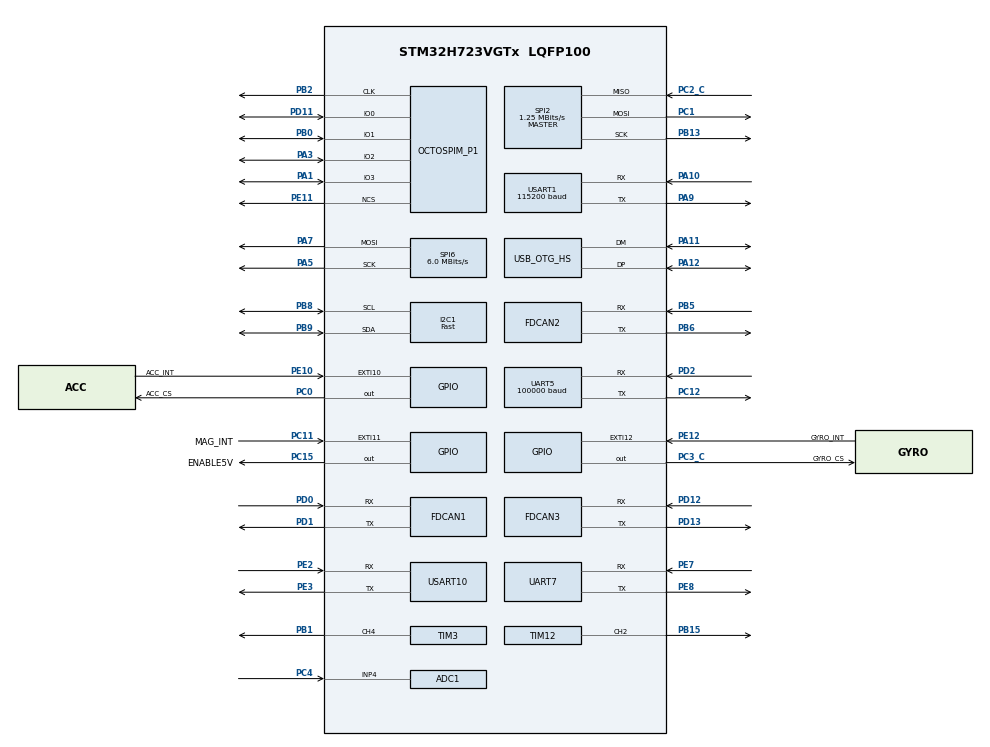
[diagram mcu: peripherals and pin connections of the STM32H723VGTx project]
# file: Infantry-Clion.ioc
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ADC1.Channel-0\#ChannelRegularConversion=ADC_CHANNEL_4
ADC1.Channel-1\#ChannelRegularConversion=ADC_CHANNEL_4
ADC1.ClockPrescaler=ADC_CLOCK_ASYNC_DIV64
ADC1.ClockPrescalerADC3=ADC_CLOCK_ASYNC_DIV4
ADC1.ContinuousConvMode=ENABLE
ADC1.NbrOfConversion=2
ADC1.NbrOfConversionFlag=1
ADC1.OffsetNumber-0\#ChannelRegularConversion=ADC_OFFSET_NONE
ADC1.OffsetNumber-1\#ChannelRegularConversion=ADC_OFFSET_NONE
ADC1.OffsetSignedSaturation-0\#ChannelRegularConversion=DISABLE
ADC1.OffsetSignedSaturation-1\#ChannelRegularConversion=DISABLE
ADC1.Rank-0\#ChannelRegularConversion=1
ADC1.Rank-1\#ChannelRegularConversion=2
ADC1.SamplingTime-0\#ChannelRegularConversion=ADC_SAMPLETIME_32CYCLES_5
ADC1.SamplingTime-1\#ChannelRegularConversion=ADC_SAMPLETIME_32CYCLES_5
ADC1.master=1
ADC3.Channel-1\#ChannelRegularConversion=ADC_CHANNEL_TEMPSENSOR
ADC3.ClockPrescaler=ADC_CLOCK_ASYNC_DIV64
ADC3.ClockPrescalerADC3=ADC_CLOCK_ASYNC_DIV4
ADC3.NbrOfConversionFlag=1
ADC3.OffsetNumber-1\#ChannelRegularConversion=ADC_OFFSET_NONE
ADC3.OffsetSign-1\#ChannelRegularConversion=ADC3_OFFSET_SIGN_NEGATIVE
ADC3.Rank-1\#ChannelRegularConversion=1
ADC3.SamplingTime-1\#ChannelRegularConversion=ADC3_SAMPLETIME_640CYCLES_5
CORTEX_M7.AccessPermission-Cortex_Memory_Protection_Unit_Region0_Settings=MPU_REGION_PRIV_RW_URO
CORTEX_M7.AccessPermission-Cortex_Memory_Protection_Unit_Region1_Settings=MPU_REGION_FULL_ACCESS
CORTEX_M7.BaseAddress-Cortex_Memory_Protection_Unit_Region0_Settings=0x08000000
CORTEX_M7.BaseAddress-Cortex_Memory_Protection_Unit_Region1_Settings=0x20000000
CORTEX_M7.CPU_DCache=Disabled
CORTEX_M7.CPU_ICache=Enabled
CORTEX_M7.Enable-Cortex_Memory_Protection_Unit_Region0_Settings=MPU_REGION_ENABLE
CORTEX_M7.Enable-Cortex_Memory_Protection_Unit_Region1_Settings=MPU_REGION_ENABLE
CORTEX_M7.IsCacheable-Cortex_Memory_Protection_Unit_Region0_Settings=MPU_ACCESS_CACHEABLE
CORTEX_M7.MPU_Control=MPU_PRIVILEGED_DEFAULT
CORTEX_M7.Number-Cortex_Memory_Protection_Unit_Region1_Settings=MPU_REGION_NUMBER1
CORTEX_M7.Size-Cortex_Memory_Protection_Unit_Region0_Settings=MPU_REGION_SIZE_1MB
CORTEX_M7.Size-Cortex_Memory_Protection_Unit_Region1_Settings=MPU_REGION_SIZE_512MB
CORTEX_M7.SubRegionDisable-Cortex_Memory_Protection_Unit_Region1_Settings=0xAC
CORTEX_M7.TypeExtField-Cortex_Memory_Protection_Unit_Region1_Settings=MPU_TEX_LEVEL1
Dma.Request0=USART1_RX
Dma.Request1=USART1_TX
Dma.Request2=UART7_RX
Dma.Request3=UART7_TX
Dma.Request4=USART10_RX
Dma.Request5=USART10_TX
Dma.Request6=SPI2_TX
Dma.Request7=SPI2_RX
Dma.Request8=UART5_RX
Dma.SPI2_RX.7.Direction=DMA_PERIPH_TO_MEMORY
Dma.SPI2_RX.7.EventEnable=DISABLE
Dma.SPI2_RX.7.FIFOMode=DMA_FIFOMODE_DISABLE
Dma.SPI2_RX.7.Instance=DMA1_Stream7
Dma.SPI2_RX.7.MemDataAlignment=DMA_MDATAALIGN_BYTE
Dma.SPI2_RX.7.MemInc=DMA_MINC_ENABLE
Dma.SPI2_RX.7.Mode=DMA_NORMAL
Dma.SPI2_RX.7.PeriphDataAlignment=DMA_PDATAALIGN_BYTE
Dma.SPI2_RX.7.PeriphInc=DMA_PINC_DISABLE
Dma.SPI2_RX.7.Polarity=HAL_DMAMUX_REQ_GEN_RISING
Dma.SPI2_RX.7.Priority=DMA_PRIORITY_VERY_HIGH
Dma.SPI2_RX.7.RequestNumber=1
Dma.SPI2_RX.7.SignalID=NONE
Dma.SPI2_RX.7.SyncEnable=DISABLE
Dma.SPI2_RX.7.SyncPolarity=HAL_DMAMUX_SYNC_NO_EVENT
Dma.SPI2_RX.7.SyncRequestNumber=1
Dma.SPI2_RX.7.SyncSignalID=NONE
Dma.SPI2_TX.6.Direction=DMA_MEMORY_TO_PERIPH
Dma.SPI2_TX.6.EventEnable=DISABLE
Dma.SPI2_TX.6.FIFOMode=DMA_FIFOMODE_DISABLE
Dma.SPI2_TX.6.Instance=DMA1_Stream6
Dma.SPI2_TX.6.MemDataAlignment=DMA_MDATAALIGN_BYTE
Dma.SPI2_TX.6.MemInc=DMA_MINC_ENABLE
Dma.SPI2_TX.6.Mode=DMA_NORMAL
Dma.SPI2_TX.6.PeriphDataAlignment=DMA_PDATAALIGN_BYTE
Dma.SPI2_TX.6.PeriphInc=DMA_PINC_DISABLE
Dma.SPI2_TX.6.Polarity=HAL_DMAMUX_REQ_GEN_RISING
Dma.SPI2_TX.6.Priority=DMA_PRIORITY_HIGH
Dma.SPI2_TX.6.RequestNumber=1
Dma.SPI2_TX.6.SignalID=NONE
Dma.SPI2_TX.6.SyncEnable=DISABLE
Dma.SPI2_TX.6.SyncPolarity=HAL_DMAMUX_SYNC_NO_EVENT
Dma.SPI2_TX.6.SyncRequestNumber=1
Dma.SPI2_TX.6.SyncSignalID=NONE
Dma.UART5_RX.8.Direction=DMA_PERIPH_TO_MEMORY
Dma.UART5_RX.8.EventEnable=DISABLE
Dma.UART5_RX.8.FIFOMode=DMA_FIFOMODE_DISABLE
Dma.UART5_RX.8.Instance=DMA1_Stream0
Dma.UART5_RX.8.MemDataAlignment=DMA_MDATAALIGN_BYTE
Dma.UART5_RX.8.MemInc=DMA_MINC_ENABLE
Dma.UART5_RX.8.Mode=DMA_NORMAL
Dma.UART5_RX.8.PeriphDataAlignment=DMA_PDATAALIGN_BYTE
Dma.UART5_RX.8.PeriphInc=DMA_PINC_DISABLE
Dma.UART5_RX.8.Polarity=HAL_DMAMUX_REQ_GEN_RISING
Dma.UART5_RX.8.Priority=DMA_PRIORITY_HIGH
Dma.UART5_RX.8.RequestNumber=1
Dma.UART5_RX.8.SignalID=NONE
Dma.UART5_RX.8.SyncEnable=DISABLE
Dma.UART5_RX.8.SyncPolarity=HAL_DMAMUX_SYNC_NO_EVENT
Dma.UART5_RX.8.SyncRequestNumber=1
Dma.UART5_RX.8.SyncSignalID=NONE
Dma.UART7_RX.2.Direction=DMA_PERIPH_TO_MEMORY
Dma.UART7_RX.2.EventEnable=DISABLE
Dma.UART7_RX.2.FIFOMode=DMA_FIFOMODE_DISABLE
Dma.UART7_RX.2.Instance=DMA1_Stream2
Dma.UART7_RX.2.MemDataAlignment=DMA_MDATAALIGN_BYTE
Dma.UART7_RX.2.MemInc=DMA_MINC_ENABLE
Dma.UART7_RX.2.Mode=DMA_NORMAL
Dma.UART7_RX.2.PeriphDataAlignment=DMA_PDATAALIGN_BYTE
Dma.UART7_RX.2.PeriphInc=DMA_PINC_DISABLE
Dma.UART7_RX.2.Polarity=HAL_DMAMUX_REQ_GEN_RISING
Dma.UART7_RX.2.Priority=DMA_PRIORITY_VERY_HIGH
Dma.UART7_RX.2.RequestNumber=1
Dma.UART7_RX.2.SignalID=NONE
Dma.UART7_RX.2.SyncEnable=DISABLE
Dma.UART7_RX.2.SyncPolarity=HAL_DMAMUX_SYNC_NO_EVENT
Dma.UART7_RX.2.SyncRequestNumber=1
Dma.UART7_RX.2.SyncSignalID=NONE
Dma.UART7_TX.3.Direction=DMA_MEMORY_TO_PERIPH
Dma.UART7_TX.3.EventEnable=DISABLE
Dma.UART7_TX.3.FIFOMode=DMA_FIFOMODE_DISABLE
Dma.UART7_TX.3.Instance=DMA1_Stream3
Dma.UART7_TX.3.MemDataAlignment=DMA_MDATAALIGN_BYTE
Dma.UART7_TX.3.MemInc=DMA_MINC_ENABLE
Dma.UART7_TX.3.Mode=DMA_NORMAL
Dma.UART7_TX.3.PeriphDataAlignment=DMA_PDATAALIGN_BYTE
Dma.UART7_TX.3.PeriphInc=DMA_PINC_DISABLE
Dma.UART7_TX.3.Polarity=HAL_DMAMUX_REQ_GEN_RISING
Dma.UART7_TX.3.Priority=DMA_PRIORITY_VERY_HIGH
Dma.UART7_TX.3.RequestNumber=1
Dma.UART7_TX.3.SignalID=NONE
Dma.UART7_TX.3.SyncEnable=DISABLE
Dma.UART7_TX.3.SyncPolarity=HAL_DMAMUX_SYNC_NO_EVENT
Dma.UART7_TX.3.SyncRequestNumber=1
Dma.UART7_TX.3.SyncSignalID=NONE
Dma.USART10_RX.4.Direction=DMA_PERIPH_TO_MEMORY
Dma.USART10_RX.4.EventEnable=DISABLE
Dma.USART10_RX.4.FIFOMode=DMA_FIFOMODE_DISABLE
Dma.USART10_RX.4.Instance=DMA1_Stream4
Dma.USART10_RX.4.MemDataAlignment=DMA_MDATAALIGN_BYTE
Dma.USART10_RX.4.MemInc=DMA_MINC_ENABLE
Dma.USART10_RX.4.Mode=DMA_NORMAL
Dma.USART10_RX.4.PeriphDataAlignment=DMA_PDATAALIGN_BYTE
Dma.USART10_RX.4.PeriphInc=DMA_PINC_DISABLE
Dma.USART10_RX.4.Polarity=HAL_DMAMUX_REQ_GEN_RISING
Dma.USART10_RX.4.Priority=DMA_PRIORITY_VERY_HIGH
Dma.USART10_RX.4.RequestNumber=1
Dma.USART10_RX.4.SignalID=NONE
Dma.USART10_RX.4.SyncEnable=DISABLE
Dma.USART10_RX.4.SyncPolarity=HAL_DMAMUX_SYNC_NO_EVENT
Dma.USART10_RX.4.SyncRequestNumber=1
Dma.USART10_RX.4.SyncSignalID=NONE
Dma.USART10_TX.5.Direction=DMA_MEMORY_TO_PERIPH
Dma.USART10_TX.5.EventEnable=DISABLE
Dma.USART10_TX.5.FIFOMode=DMA_FIFOMODE_DISABLE
Dma.USART10_TX.5.Instance=DMA1_Stream5
Dma.USART10_TX.5.MemDataAlignment=DMA_MDATAALIGN_BYTE
Dma.USART10_TX.5.MemInc=DMA_MINC_ENABLE
Dma.USART10_TX.5.Mode=DMA_NORMAL
Dma.USART10_TX.5.PeriphDataAlignment=DMA_PDATAALIGN_BYTE
Dma.USART10_TX.5.PeriphInc=DMA_PINC_DISABLE
Dma.USART10_TX.5.Polarity=HAL_DMAMUX_REQ_GEN_RISING
Dma.USART10_TX.5.Priority=DMA_PRIORITY_VERY_HIGH
Dma.USART10_TX.5.RequestNumber=1
Dma.USART10_TX.5.SignalID=NONE
Dma.USART10_TX.5.SyncEnable=DISABLE
Dma.USART10_TX.5.SyncPolarity=HAL_DMAMUX_SYNC_NO_EVENT
Dma.USART10_TX.5.SyncRequestNumber=1
Dma.USART10_TX.5.SyncSignalID=NONE
Dma.USART1_RX.0.Direction=DMA_PERIPH_TO_MEMORY
Dma.USART1_RX.0.EventEnable=DISABLE
Dma.USART1_RX.0.FIFOMode=DMA_FIFOMODE_DISABLE
Dma.USART1_RX.0.Instance=DMA1_Stream1
Dma.USART1_RX.0.MemDataAlignment=DMA_MDATAALIGN_BYTE
Dma.USART1_RX.0.MemInc=DMA_MINC_ENABLE
Dma.USART1_RX.0.Mode=DMA_NORMAL
Dma.USART1_RX.0.PeriphDataAlignment=DMA_PDATAALIGN_BYTE
Dma.USART1_RX.0.PeriphInc=DMA_PINC_DISABLE
Dma.USART1_RX.0.Polarity=HAL_DMAMUX_REQ_GEN_RISING
Dma.USART1_RX.0.Priority=DMA_PRIORITY_VERY_HIGH
Dma.USART1_RX.0.RequestNumber=1
Dma.USART1_RX.0.SignalID=NONE
Dma.USART1_RX.0.SyncEnable=DISABLE
Dma.USART1_RX.0.SyncPolarity=HAL_DMAMUX_SYNC_NO_EVENT
Dma.USART1_RX.0.SyncRequestNumber=1
Dma.USART1_RX.0.SyncSignalID=NONE
Dma.USART1_TX.1.Direction=DMA_MEMORY_TO_PERIPH
Dma.USART1_TX.1.EventEnable=DISABLE
Dma.USART1_TX.1.FIFOMode=DMA_FIFOMODE_DISABLE
Dma.USART1_TX.1.Instance=DMA2_Stream0
Dma.USART1_TX.1.MemDataAlignment=DMA_MDATAALIGN_BYTE
Dma.USART1_TX.1.MemInc=DMA_MINC_ENABLE
Dma.USART1_TX.1.Mode=DMA_NORMAL
Dma.USART1_TX.1.PeriphDataAlignment=DMA_PDATAALIGN_BYTE
Dma.USART1_TX.1.PeriphInc=DMA_PINC_DISABLE
Dma.USART1_TX.1.Polarity=HAL_DMAMUX_REQ_GEN_RISING
Dma.USART1_TX.1.Priority=DMA_PRIORITY_VERY_HIGH
Dma.USART1_TX.1.RequestNumber=1
Dma.USART1_TX.1.SignalID=NONE
Dma.USART1_TX.1.SyncEnable=DISABLE
Dma.USART1_TX.1.SyncPolarity=HAL_DMAMUX_SYNC_NO_EVENT
Dma.USART1_TX.1.SyncRequestNumber=1
Dma.USART1_TX.1.SyncSignalID=NONE
FDCAN1.AutoRetransmission=ENABLE
FDCAN1.CalculateBaudRateNominal=1000000
FDCAN1.CalculateTimeBitNominal=1000
FDCAN1.CalculateTimeQuantumNominal=50.0
FDCAN1.DataPrescaler=1
FDCAN1.DataSyncJumpWidth=2
FDCAN1.DataTimeSeg1=13
FDCAN1.DataTimeSeg2=2
FDCAN1.ExtFiltersNbr=0
FDCAN1.Mode=FDCAN_MODE_NORMAL
FDCAN1.NominalPrescaler=1
FDCAN1.NominalSyncJumpWidth=20
FDCAN1.NominalTimeSeg1=14
FDCAN1.NominalTimeSeg2=5
FDCAN1.ProtocolException=ENABLE
FDCAN1.RxBuffersNbr=0
FDCAN1.RxFifo0ElmtsNbr=4
FDCAN1.RxFifo1ElmtsNbr=0
FDCAN1.StdFiltersNbr=1
FDCAN1.TxBuffersNbr=0
FDCAN1.TxEventsNbr=0
FDCAN1.TxFifoQueueElmtsNbr=4
FDCAN1.TxFifoQueueMode=FDCAN_TX_FIFO_OPERATION
FDCAN2.AutoRetransmission=ENABLE
FDCAN2.CalculateBaudRateNominal=1000000
FDCAN2.CalculateTimeBitNominal=1000
FDCAN2.CalculateTimeQuantumNominal=50.0
FDCAN2.DataSyncJumpWidth=2
FDCAN2.DataTimeSeg1=13
FDCAN2.DataTimeSeg2=2
FDCAN2.ExtFiltersNbr=0
FDCAN2.MessageRAMOffset=0x300
FDCAN2.Mode=FDCAN_MODE_NORMAL
FDCAN2.NominalPrescaler=1
FDCAN2.NominalSyncJumpWidth=20
FDCAN2.NominalTimeSeg1=14
FDCAN2.NominalTimeSeg2=5
FDCAN2.ProtocolException=ENABLE
FDCAN2.RxBuffersNbr=0
FDCAN2.RxFifo0ElmtsNbr=4
FDCAN2.RxFifo1ElmtsNbr=0
FDCAN2.StdFiltersNbr=1
FDCAN2.TxBuffersNbr=0
FDCAN2.TxEventsNbr=0
FDCAN2.TxFifoQueueElmtsNbr=4
FDCAN3.AutoRetransmission=ENABLE
FDCAN3.CalculateBaudRateNominal=1000000
FDCAN3.CalculateTimeBitNominal=1000
FDCAN3.CalculateTimeQuantumNominal=50.0
FDCAN3.DataSyncJumpWidth=2
FDCAN3.DataTimeSeg1=13
FDCAN3.DataTimeSeg2=2
FDCAN3.ExtFiltersNbr=0
FDCAN3.MessageRAMOffset=0x600
FDCAN3.Mode=FDCAN_MODE_NORMAL
FDCAN3.NominalPrescaler=1
FDCAN3.NominalSyncJumpWidth=20
FDCAN3.NominalTimeSeg1=14
FDCAN3.NominalTimeSeg2=5
FDCAN3.ProtocolException=ENABLE
FDCAN3.RxBuffersNbr=0
FDCAN3.RxFifo0ElmtsNbr=4
FDCAN3.RxFifo1ElmtsNbr=0
FDCAN3.StdFiltersNbr=1
FDCAN3.TxBuffersNbr=0
FDCAN3.TxEventsNbr=0
FDCAN3.TxFifoQueueElmtsNbr=4
FREERTOS.BinarySemaphores01=imuBinarySem01,Dynamic,NULL,Available
FREERTOS.INCLUDE_xEventGroupSetBitFromISR=1
FREERTOS.INCLUDE_xSemaphoreGetMutexHolder=1
FREERTOS.INCLUDE_xTaskGetHandle=1
FREERTOS.Tasks01=defaultTask,24,128,StartDefaultTask,Default,NULL,Dynamic,NULL,NULL;ledTask,8,128,led_task,As external,NULL,Dynamic,NULL,NULL;imuTask,49,128,imu_task,As external,NULL,Dynamic,NULL,NULL;usbTask,8,128,usb_task,As external,NULL,Dynamic,NULL,NULL;refereeTask,8,128,referee_task,As external,NULL,Dynamic,NULL,NULL;chassisTask,40,128,chassis_task,As external,NULL,Dynamic,NULL,NULL;detectTask,8,128,detect_task,As external,NULL,Dynamic,NULL,NULL;remoteControlTa,8,128,remote_control_task,As external,NULL,Dynamic,NULL,NULL;gimbalTask,48,128,gimbal_task,As external,NULL,Dynamic,NULL,NULL;buzzerTask,8,128,buzzer_task,As external,NULL,Dynamic,NULL,NULL;shootTask,43,128,shoot_task,As external,NULL,Dynamic,NULL,NULL;watchTask,48,128,watch_task,As external,NULL,Dynamic,NULL,NULL;uiTask,8,128,ui_task,As external,NULL,Dynamic,NULL,NULL;autoShoot,48,128,auto_shoot_task,As external,NULL,Dynamic,NULL,NULL
FREERTOS.configENABLE_FPU=1
FREERTOS.configGENERATE_RUN_TIME_STATS=1
FREERTOS.configLIBRARY_MAX_SYSCALL_INTERRUPT_PRIORITY=5
FREERTOS.configUSE_NEWLIB_REENTRANT=1
FREERTOS.configUSE_STATS_FORMATTING_FUNCTIONS=1
I2C1.CustomTiming=Disabled
I2C1.I2C_Speed_Mode=I2C_Fast
I2C1.Timing=0x00B03FDB
Mcu.Family=STM32H7
Mcu.Name=STM32H723VGTx
Mcu.Package=LQFP100
NVIC.DMA1_Stream0_IRQn=true\:5\:0\:false\:false\:true\:true\:false\:true\:true
NVIC.DMA1_Stream1_IRQn=true\:5\:0\:false\:false\:true\:true\:false\:true\:true
NVIC.DMA1_Stream2_IRQn=true\:5\:0\:false\:false\:true\:true\:false\:true\:true
NVIC.DMA1_Stream3_IRQn=true\:5\:0\:false\:false\:true\:true\:false\:true\:true
NVIC.DMA1_Stream4_IRQn=true\:5\:0\:false\:false\:true\:true\:false\:true\:true
NVIC.DMA1_Stream5_IRQn=true\:5\:0\:false\:false\:true\:true\:false\:true\:true
NVIC.DMA1_Stream6_IRQn=true\:5\:0\:false\:false\:true\:true\:false\:true\:true
NVIC.DMA1_Stream7_IRQn=true\:5\:0\:false\:false\:true\:true\:false\:true\:true
NVIC.DMA2_Stream0_IRQn=true\:5\:0\:false\:false\:true\:true\:false\:true\:true
NVIC.EXTI15_10_IRQn=true\:10\:0\:true\:false\:true\:true\:true\:true\:true
NVIC.FDCAN1_IT0_IRQn=true\:5\:0\:true\:false\:true\:true\:true\:true\:true
NVIC.FDCAN2_IT0_IRQn=true\:5\:0\:false\:false\:true\:true\:true\:true\:true
NVIC.FDCAN3_IT0_IRQn=true\:5\:0\:true\:false\:true\:true\:true\:true\:true
NVIC.FDCAN3_IT1_IRQn=true\:5\:0\:false\:false\:true\:true\:true\:true\:true
NVIC.OTG_HS_IRQn=true\:5\:0\:false\:false\:true\:true\:true\:true\:true
NVIC.PriorityGroup=NVIC_PRIORITYGROUP_4
NVIC.SPI2_IRQn=true\:5\:0\:false\:false\:true\:true\:false\:true\:true
NVIC.TIM17_IRQn=true\:5\:0\:false\:false\:true\:true\:true\:true\:true
NVIC.TIM1_UP_IRQn=true\:5\:0\:true\:false\:true\:false\:false\:true\:true
NVIC.TIM24_IRQn=true\:5\:0\:false\:false\:true\:true\:true\:true\:true
NVIC.TimeBase=TIM1_UP_IRQn
NVIC.TimeBaseIP=TIM1
NVIC.UART5_IRQn=true\:5\:0\:false\:false\:true\:true\:true\:true\:true
NVIC.UART7_IRQn=true\:5\:0\:false\:false\:true\:true\:true\:true\:true
NVIC.USART10_IRQn=true\:5\:0\:false\:false\:true\:true\:true\:true\:true
NVIC.USART1_IRQn=true\:5\:0\:false\:false\:true\:true\:true\:true\:true
OCTOSPI2.ClockMode=HAL_OSPI_CLOCK_MODE_3
OCTOSPI2.ClockPrescaler=3
OCTOSPI2.DeviceSize=23
OCTOSPI2.DeviceType=SPI_DEVICE_FLASH
OCTOSPI2.FifoThreshold=8
OCTOSPI2.SampleShifting=HAL_OSPI_SAMPLE_SHIFTING_HALFCYCLE
PA1.Mode=OCTOSPI2_IOL_Port1L
PA1.Signal=OCTOSPIM_P1_IO3
PA10.Mode=Asynchronous
PA10.Signal=USART1_RX
PA11.Mode=Device_Only_FS
PA11.Signal=USB_OTG_HS_DM
PA12.Mode=Device_Only_FS
PA12.Signal=USB_OTG_HS_DP
PA13(JTMS/SWDIO).Mode=Serial_Wire
PA13(JTMS/SWDIO).Signal=DEBUG_JTMS-SWDIO
PA14(JTCK/SWCLK).Mode=Serial_Wire
PA14(JTCK/SWCLK).Signal=DEBUG_JTCK-SWCLK
PA3.Mode=OCTOSPI2_IOL_Port1L
PA3.Signal=OCTOSPIM_P1_IO2
PA5.GPIO_PuPd=GPIO_NOPULL
PA5.GPIO_Speed=GPIO_SPEED_FREQ_VERY_HIGH
PA5.Mode=TX_Only_Simplex_Unidirect_Master
PA5.Signal=SPI6_SCK
PA7.GPIO_PuPd=GPIO_NOPULL
PA7.GPIO_Speed=GPIO_SPEED_FREQ_VERY_HIGH
PA7.Mode=TX_Only_Simplex_Unidirect_Master
PA7.Signal=SPI6_MOSI
PA9.Mode=Asynchronous
PA9.Signal=USART1_TX
PB0.Mode=OCTOSPI2_IOL_Port1L
PB0.Signal=OCTOSPIM_P1_IO1
PB1.Signal=S_TIM3_CH4
PB13.Mode=Full_Duplex_Master
PB13.Signal=SPI2_SCK
PB15.GPIO_Speed=GPIO_SPEED_FREQ_HIGH
PB15.Signal=S_TIM12_CH2
PB2.Mode=O2_P1_CLK
PB2.Signal=OCTOSPIM_P1_CLK
PB5.Mode=FDCAN_Activate
PB5.Signal=FDCAN2_RX
PB6.Mode=FDCAN_Activate
PB6.Signal=FDCAN2_TX
PB8.GPIO_Speed=GPIO_SPEED_FREQ_HIGH
PB8.Mode=I2C
PB8.Signal=I2C1_SCL
PB9.GPIO_Speed=GPIO_SPEED_FREQ_HIGH
PB9.Mode=I2C
PB9.Signal=I2C1_SDA
PC0.GPIO_Label=ACC_CS
PC0.GPIO_Speed=GPIO_SPEED_FREQ_VERY_HIGH
PC0.PinState=GPIO_PIN_SET
PC0.Signal=GPIO_Output
PC1.Mode=Full_Duplex_Master
PC1.Signal=SPI2_MOSI
PC11.GPIO_Label=MAG_INT
PC11.Signal=GPXTI11
PC12.GPIO_ModeDefaultPP=GPIO_MODE_AF_PP
PC12.Mode=Asynchronous
PC12.Signal=UART5_TX
PC15-OSC32_OUT.GPIO_Label=ENABLE5V
PC15-OSC32_OUT.GPIO_PuPd=GPIO_NOPULL
PC15-OSC32_OUT.PinState=GPIO_PIN_SET
PC15-OSC32_OUT.Signal=GPIO_Output
PC2_C.Mode=Full_Duplex_Master
PC2_C.Signal=SPI2_MISO
PC3_C.GPIO_Label=GYRO_CS
PC3_C.GPIO_Speed=GPIO_SPEED_FREQ_VERY_HIGH
PC3_C.PinState=GPIO_PIN_SET
PC3_C.Signal=GPIO_Output
PC4.Signal=ADCx_INP4
PD0.Mode=FDCAN_Activate
PD0.Signal=FDCAN1_RX
PD1.Mode=FDCAN_Activate
PD1.Signal=FDCAN1_TX
PD11.Mode=OCTOSPI2_IOL_Port1L
PD11.Signal=OCTOSPIM_P1_IO0
PD12.Mode=FDCAN_Activate
PD12.Signal=FDCAN3_RX
PD13.Mode=FDCAN_Activate
PD13.Signal=FDCAN3_TX
PD2.GPIO_ModeDefaultPP=GPIO_MODE_AF_PP
PD2.Mode=Asynchronous
PD2.Signal=UART5_RX
PE10.GPIO_Label=ACC_INT
PE10.Signal=GPXTI10
PE11.Mode=OCTOSPI2_Port1_NCS
PE11.Signal=OCTOSPIM_P1_NCS
PE12.GPIO_Label=GYRO_INT
PE12.Signal=GPXTI12
PE2.Mode=Asynchronous
PE2.Signal=USART10_RX
PE3.Mode=Asynchronous
PE3.Signal=USART10_TX
PE7.Mode=Asynchronous
PE7.Signal=UART7_RX
PE8.Mode=Asynchronous
PE8.Signal=UART7_TX
PH0-OSC_IN.Mode=HSE-External-Oscillator
PH0-OSC_IN.Signal=RCC_OSC_IN
PH1-OSC_OUT.Mode=HSE-External-Oscillator
PH1-OSC_OUT.Signal=RCC_OSC_OUT
ProjectManager.HeapSize=0x200
ProjectManager.StackSize=0x400
ProjectManager.TargetToolchain=STM32CubeIDE
RCC.ADCFreq_Value=96000000
RCC.APB1Freq_Value=120000000
RCC.APB2Freq_Value=120000000
RCC.APB3Freq_Value=120000000
RCC.APB4Freq_Value=120000000
RCC.CortexFreq_Value=480000000
RCC.D1PPRE=RCC_APB3_DIV2
RCC.D2PPRE1=RCC_APB1_DIV2
RCC.D2PPRE2=RCC_APB2_DIV2
RCC.D3PPRE=RCC_APB4_DIV2
RCC.DIVM1=2
RCC.DIVM2=2
RCC.DIVN1=40
RCC.DIVN2=16
RCC.DIVP1=1
RCC.DIVQ1=24
RCC.HCLKFreq_Value=240000000
RCC.HPRE=RCC_HCLK_DIV2
RCC.HSE_VALUE=24000000
RCC.PLL2FRACN=0
RCC.PLLFRACN=0
RCC.PLLSourceVirtual=RCC_PLLSOURCE_HSE
RCC.SPI6CLockSelection=RCC_SPI6CLKSOURCE_HSE
RCC.SYSCLKFreq_VALUE=480000000
RCC.SYSCLKSource=RCC_SYSCLKSOURCE_PLLCLK
RCC.USBCLockSelection=RCC_USBCLKSOURCE_HSI48
RCC.USBFreq_Value=48000000
SH.ADCx_INP4.0=ADC1_INP4,IN4-Single-Ended
SH.S_TIM12_CH2.0=TIM12_CH2,PWM Generation2 CH2
SH.S_TIM3_CH4.0=TIM3_CH4,PWM Generation4 CH4
SPI2.BaudRatePrescaler=SPI_BAUDRATEPRESCALER_16
SPI2.CLKPhase=SPI_PHASE_2EDGE
SPI2.CLKPolarity=SPI_POLARITY_HIGH
SPI2.CalculateBaudRate=1.25 MBits/s
SPI2.DataSize=SPI_DATASIZE_8BIT
SPI2.Direction=SPI_DIRECTION_2LINES
SPI2.Mode=SPI_MODE_MASTER
SPI2.VirtualType=VM_MASTER
SPI6.BaudRatePrescaler=SPI_BAUDRATEPRESCALER_4
SPI6.CLKPhase=SPI_PHASE_2EDGE
SPI6.CalculateBaudRate=6.0 MBits/s
SPI6.DataSize=SPI_DATASIZE_8BIT
SPI6.Direction=SPI_DIRECTION_2LINES_TXONLY
SPI6.Mode=SPI_MODE_MASTER
SPI6.VirtualType=VM_MASTER
STMicroelectronics.X-CUBE-ALGOBUILD.1.4.0.LibraryCcDSPOoLibraryJjDSPOoLibrary=true
TIM12.AutoReloadPreload=TIM_AUTORELOAD_PRELOAD_DISABLE
TIM12.Channel-PWM\ Generation2\ CH2=TIM_CHANNEL_2
TIM12.Period=2000-1
TIM12.Prescaler=24-1
TIM12.Pulse-PWM\ Generation2\ CH2=1000
TIM17.AutoReloadPreload=TIM_AUTORELOAD_PRELOAD_ENABLE
TIM17.Period=200
TIM17.Prescaler=239
TIM24.AutoReloadPreload=TIM_AUTORELOAD_PRELOAD_ENABLE
TIM24.Period=399
TIM24.Prescaler=12-1
TIM3.AutoReloadPreload=TIM_AUTORELOAD_PRELOAD_ENABLE
TIM3.Channel-PWM\ Generation4\ CH4=TIM_CHANNEL_4
TIM3.ClockDivision=TIM_CLOCKDIVISION_DIV1
TIM3.Period=12500-1
TIM3.Prescaler=24-1
UART5.BaudRate=100000
UART5.Mode=MODE_RX
UART5.Parity=PARITY_EVEN
UART5.StopBits=UART_STOPBITS_2
UART5.SwapParam=UART_ADVFEATURE_SWAP_DISABLE
UART5.WordLength=WORDLENGTH_9B
USART1.BaudRate=115200
USART1.VirtualMode-Asynchronous=VM_ASYNC
USART10.VirtualMode=VM_ASYNC
USB_DEVICE.CLASS_NAME_HS=CDC
USB_DEVICE.VirtualMode=Cdc
USB_DEVICE.VirtualModeHS=Cdc_HS
USB_OTG_HS.VirtualMode-Device_Only_FS=Device_Only_FS
VP_ADC3_TempSens_Input.Mode=IN-TempSens
VP_ADC3_Vref_Input.Mode=IN-Vrefint
VP_CRC_VS_CRC.Mode=CRC_Activate
VP_FREERTOS_VS_CMSIS_V2.Mode=CMSIS_V2
VP_MEMORYMAP_VS_MEMORYMAP.Mode=CurAppReg
VP_OCTOSPI2_VS_quad.Mode=quad_mode
VP_STMicroelectronics.X-CUBE-ALGOBUILD_VS_DSPOoLibraryJjLibrary_1.4.0_1.4.0.Mode=DSPOoLibraryJjLibrary
VP_SYS_VS_tim1.Mode=TIM1
VP_TIM17_VS_ClockSourceINT.Mode=Enable_Timer
VP_TIM24_VS_ClockSourceINT.Mode=Internal
VP_TIM3_VS_ClockSourceINT.Mode=Internal
VP_USB_DEVICE_VS_USB_DEVICE_CDC_HS.Mode=CDC_HS
board=custom

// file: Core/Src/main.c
/* USER CODE BEGIN Header */
/**
  ******************************************************************************
  * @file           : main.c
  * @brief          : Main program body
  ******************************************************************************
  * @attention
  *
  * Copyright (c) 2024 STMicroelectronics.
  * All rights reserved.
  *
  * This software is licensed under terms that can be found in the LICENSE file
  * in the root directory of this software component.
  * If no LICENSE file comes with this software, it is provided AS-IS.
  *
  ******************************************************************************
  */
/* USER CODE END Header */
#include "main.h"
#include "cmsis_os.h"
#include "adc.h"
#include "crc.h"
#include "dma.h"
#include "fdcan.h"
#include "i2c.h"
#include "memorymap.h"
#include "octospi.h"
#include "spi.h"
#include "tim.h"
#include "usart.h"
#include "usb_device.h"
#include "gpio.h"

/* USER CODE BEGIN Includes */
#include "bsp_can.h"
#include "bsp_tim.h"
/* USER CODE END Includes */

void SystemClock_Config(void);
void PeriphCommonClock_Config(void);
static void MPU_Config(void);
void MX_FREERTOS_Init(void);

int main(void)
{

  /* MPU Configuration--------------------------------------------------------*/
  MPU_Config();

  /* Enable the CPU Cache */

  /* Enable I-Cache---------------------------------------------------------*/
  SCB_EnableICache();

  /* MCU Configuration--------------------------------------------------------*/

  /* Reset of all peripherals, Initializes the Flash interface and the Systick. */
  HAL_Init();

  /* Configure the system clock */
  SystemClock_Config();

  /* Configure the peripherals common clocks */
  PeriphCommonClock_Config();

  /* Initialize all configured peripherals */
  MX_GPIO_Init();
  MX_DMA_Init();
  MX_FDCAN1_Init();
  MX_FDCAN2_Init();
  MX_FDCAN3_Init();
  MX_USART1_UART_Init();
  MX_ADC1_Init();
  MX_ADC3_Init();
  MX_TIM12_Init();
  MX_CRC_Init();
  MX_UART7_Init();
  MX_USART10_UART_Init();
  MX_SPI2_Init();
  MX_TIM3_Init();
  MX_UART5_Init();
  MX_SPI6_Init();
  MX_I2C1_Init();
  MX_TIM24_Init();
  MX_OCTOSPI2_Init();
  MX_TIM17_Init();
  /* USER CODE BEGIN 2 */
  MX_USB_DEVICE_Init();
  fdcan1_filter_init();
  fdcan2_filter_init();
  fdcan3_filter_init();

  /* USER CODE END 2 */

  /* Init scheduler */
  osKernelInitialize();

  /* Call init function for freertos objects (in cmsis_os2.c) */
  MX_FREERTOS_Init();

  /* Start scheduler */
  osKernelStart();

  /* We should never get here as control is now taken by the scheduler */

  /* Infinite loop */
	while (1)
	{

	}
}

void SystemClock_Config(void)
{
  RCC_OscInitTypeDef RCC_OscInitStruct = {0};
  RCC_ClkInitTypeDef RCC_ClkInitStruct = {0};

  /** Supply configuration update enable
  */
  HAL_PWREx_ConfigSupply(PWR_LDO_SUPPLY);

  /** Configure the main internal regulator output voltage
  */
  __HAL_PWR_VOLTAGESCALING_CONFIG(PWR_REGULATOR_VOLTAGE_SCALE0);

  while(!__HAL_PWR_GET_FLAG(PWR_FLAG_VOSRDY)) {}

  /** Initializes the RCC Oscillators according to the specified parameters
  * in the RCC_OscInitTypeDef structure.
  */
  RCC_OscInitStruct.OscillatorType = RCC_OSCILLATORTYPE_HSI48|RCC_OSCILLATORTYPE_HSE;
  RCC_OscInitStruct.HSEState = RCC_HSE_ON;
  RCC_OscInitStruct.HSI48State = RCC_HSI48_ON;
  RCC_OscInitStruct.PLL.PLLState = RCC_PLL_ON;
  RCC_OscInitStruct.PLL.PLLSource = RCC_PLLSOURCE_HSE;
  RCC_OscInitStruct.PLL.PLLM = 2;
  RCC_OscInitStruct.PLL.PLLN = 40;
  RCC_OscInitStruct.PLL.PLLP = 1;
  RCC_OscInitStruct.PLL.PLLQ = 24;
  RCC_OscInitStruct.PLL.PLLR = 2;
  RCC_OscInitStruct.PLL.PLLRGE = RCC_PLL1VCIRANGE_3;
  RCC_OscInitStruct.PLL.PLLVCOSEL = RCC_PLL1VCOWIDE;
  RCC_OscInitStruct.PLL.PLLFRACN = 0;
  if (HAL_RCC_OscConfig(&RCC_OscInitStruct) != HAL_OK)
  {
    Error_Handler();
  }

  /** Initializes the CPU, AHB and APB buses clocks
  */
  RCC_ClkInitStruct.ClockType = RCC_CLOCKTYPE_HCLK|RCC_CLOCKTYPE_SYSCLK
                              |RCC_CLOCKTYPE_PCLK1|RCC_CLOCKTYPE_PCLK2
                              |RCC_CLOCKTYPE_D3PCLK1|RCC_CLOCKTYPE_D1PCLK1;
  RCC_ClkInitStruct.SYSCLKSource = RCC_SYSCLKSOURCE_PLLCLK;
  RCC_ClkInitStruct.SYSCLKDivider = RCC_SYSCLK_DIV1;
  RCC_ClkInitStruct.AHBCLKDivider = RCC_HCLK_DIV2;
  RCC_ClkInitStruct.APB3CLKDivider = RCC_APB3_DIV2;
  RCC_ClkInitStruct.APB1CLKDivider = RCC_APB1_DIV2;
  RCC_ClkInitStruct.APB2CLKDivider = RCC_APB2_DIV2;
  RCC_ClkInitStruct.APB4CLKDivider = RCC_APB4_DIV2;

  if (HAL_RCC_ClockConfig(&RCC_ClkInitStruct, FLASH_LATENCY_3) != HAL_OK)
  {
    Error_Handler();
  }
}

void PeriphCommonClock_Config(void)
{
  RCC_PeriphCLKInitTypeDef PeriphClkInitStruct = {0};

  /** Initializes the peripherals clock
  */
  PeriphClkInitStruct.PeriphClockSelection = RCC_PERIPHCLK_ADC;
  PeriphClkInitStruct.PLL2.PLL2M = 2;
  PeriphClkInitStruct.PLL2.PLL2N = 16;
  PeriphClkInitStruct.PLL2.PLL2P = 2;
  PeriphClkInitStruct.PLL2.PLL2Q = 2;
  PeriphClkInitStruct.PLL2.PLL2R = 2;
  PeriphClkInitStruct.PLL2.PLL2RGE = RCC_PLL2VCIRANGE_3;
  PeriphClkInitStruct.PLL2.PLL2VCOSEL = RCC_PLL2VCOWIDE;
  PeriphClkInitStruct.PLL2.PLL2FRACN = 0;
  PeriphClkInitStruct.AdcClockSelection = RCC_ADCCLKSOURCE_PLL2;
  if (HAL_RCCEx_PeriphCLKConfig(&PeriphClkInitStruct) != HAL_OK)
  {
    Error_Handler();
  }
}

 /* MPU Configuration */

void MPU_Config(void)
{
  MPU_Region_InitTypeDef MPU_InitStruct = {0};

  /* Disables the MPU */
  HAL_MPU_Disable();

  /** Initializes and configures the Region and the memory to be protected
  */
  MPU_InitStruct.Enable = MPU_REGION_ENABLE;
  MPU_InitStruct.Number = MPU_REGION_NUMBER0;
  MPU_InitStruct.BaseAddress = 0x08000000;
  MPU_InitStruct.Size = MPU_REGION_SIZE_1MB;
  MPU_InitStruct.SubRegionDisable = 0x0;
  MPU_InitStruct.TypeExtField = MPU_TEX_LEVEL0;
  MPU_InitStruct.AccessPermission = MPU_REGION_PRIV_RW_URO;
  MPU_InitStruct.DisableExec = MPU_INSTRUCTION_ACCESS_ENABLE;
  MPU_InitStruct.IsShareable = MPU_ACCESS_NOT_SHAREABLE;
  MPU_InitStruct.IsCacheable = MPU_ACCESS_CACHEABLE;
  MPU_InitStruct.IsBufferable = MPU_ACCESS_NOT_BUFFERABLE;

  HAL_MPU_ConfigRegion(&MPU_InitStruct);

  /** Initializes and configures the Region and the memory to be protected
  */
  MPU_InitStruct.Number = MPU_REGION_NUMBER1;
  MPU_InitStruct.BaseAddress = 0x20000000;
  MPU_InitStruct.Size = MPU_REGION_SIZE_512MB;
  MPU_InitStruct.SubRegionDisable = 0xAC;
  MPU_InitStruct.TypeExtField = MPU_TEX_LEVEL1;
  MPU_InitStruct.AccessPermission = MPU_REGION_FULL_ACCESS;
  MPU_InitStruct.IsCacheable = MPU_ACCESS_NOT_CACHEABLE;

  HAL_MPU_ConfigRegion(&MPU_InitStruct);
  /* Enables the MPU */
  HAL_MPU_Enable(MPU_PRIVILEGED_DEFAULT);

}

void HAL_TIM_PeriodElapsedCallback(TIM_HandleTypeDef *htim)
{
  if (htim->Instance == TIM1) {
    HAL_IncTick();
  }
  /* USER CODE BEGIN Callback 1 */
  // 不使用HAL原生回调函数的原因是HAL库自身的回调函数会在中断中调用FreeRTOS的API
	USER_TIM_PeriodElapsedCallback(htim);
  /* USER CODE END Callback 1 */
}

void Error_Handler(void)
{
	__disable_irq();
	while (1)
	{
	}
}

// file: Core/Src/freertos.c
/* USER CODE BEGIN Header */
/**
  ******************************************************************************
  * File Name          : freertos.c
  * Description        : Code for freertos applications
  ******************************************************************************
  * @attention
  *
  * Copyright (c) 2024 STMicroelectronics.
  * All rights reserved.
  *
  * This software is licensed under terms that can be found in the LICENSE file
  * in the root directory of this software component.
  * If no LICENSE file comes with this software, it is provided AS-IS.
  *
  ******************************************************************************
  */
/* USER CODE END Header */

#include "FreeRTOS.h"
#include "task.h"
#include "main.h"
#include "cmsis_os.h"

/* USER CODE BEGIN Includes */
#include "tick.h"
/* USER CODE END Includes */

/* USER CODE BEGIN Variables */
extern volatile uint32_t tick_10us;
/* USER CODE END Variables */
/* Definitions for defaultTask */
osThreadId_t defaultTaskHandle;
const osThreadAttr_t defaultTask_attributes = {
  .name = "defaultTask",
  .stack_size = 128 * 4,
  .priority = (osPriority_t) osPriorityNormal,
};
/* Definitions for ledTask */
osThreadId_t ledTaskHandle;
const osThreadAttr_t ledTask_attributes = {
  .name = "ledTask",
  .stack_size = 128 * 4,
  .priority = (osPriority_t) osPriorityLow,
};
/* Definitions for imuTask */
osThreadId_t imuTaskHandle;
const osThreadAttr_t imuTask_attributes = {
  .name = "imuTask",
  .stack_size = 128 * 4,
  .priority = (osPriority_t) osPriorityRealtime1,
};
/* Definitions for usbTask */
osThreadId_t usbTaskHandle;
const osThreadAttr_t usbTask_attributes = {
  .name = "usbTask",
  .stack_size = 128 * 4,
  .priority = (osPriority_t) osPriorityLow,
};
/* Definitions for refereeTask */
osThreadId_t refereeTaskHandle;
const osThreadAttr_t refereeTask_attributes = {
  .name = "refereeTask",
  .stack_size = 128 * 4,
  .priority = (osPriority_t) osPriorityLow,
};
/* Definitions for chassisTask */
osThreadId_t chassisTaskHandle;
const osThreadAttr_t chassisTask_attributes = {
  .name = "chassisTask",
  .stack_size = 128 * 4,
  .priority = (osPriority_t) osPriorityHigh,
};
/* Definitions for detectTask */
osThreadId_t detectTaskHandle;
const osThreadAttr_t detectTask_attributes = {
  .name = "detectTask",
  .stack_size = 128 * 4,
  .priority = (osPriority_t) osPriorityLow,
};
/* Definitions for remoteControlTa */
osThreadId_t remoteControlTaHandle;
const osThreadAttr_t remoteControlTa_attributes = {
  .name = "remoteControlTa",
  .stack_size = 128 * 4,
  .priority = (osPriority_t) osPriorityLow,
};
/* Definitions for gimbalTask */
osThreadId_t gimbalTaskHandle;
const osThreadAttr_t gimbalTask_attributes = {
  .name = "gimbalTask",
  .stack_size = 128 * 4,
  .priority = (osPriority_t) osPriorityRealtime,
};
/* Definitions for buzzerTask */
osThreadId_t buzzerTaskHandle;
const osThreadAttr_t buzzerTask_attributes = {
  .name = "buzzerTask",
  .stack_size = 128 * 4,
  .priority = (osPriority_t) osPriorityLow,
};
/* Definitions for shootTask */
osThreadId_t shootTaskHandle;
const osThreadAttr_t shootTask_attributes = {
  .name = "shootTask",
  .stack_size = 128 * 4,
  .priority = (osPriority_t) osPriorityHigh3,
};
/* Definitions for watchTask */
osThreadId_t watchTaskHandle;
const osThreadAttr_t watchTask_attributes = {
  .name = "watchTask",
  .stack_size = 128 * 4,
  .priority = (osPriority_t) osPriorityRealtime,
};
/* Definitions for uiTask */
osThreadId_t uiTaskHandle;
const osThreadAttr_t uiTask_attributes = {
  .name = "uiTask",
  .stack_size = 128 * 4,
  .priority = (osPriority_t) osPriorityLow,
};
/* Definitions for autoShoot */
osThreadId_t autoShootHandle;
const osThreadAttr_t autoShoot_attributes = {
  .name = "autoShoot",
  .stack_size = 128 * 4,
  .priority = (osPriority_t) osPriorityRealtime,
};
/* Definitions for imuBinarySem01 */
osSemaphoreId_t imuBinarySem01Handle;
const osSemaphoreAttr_t imuBinarySem01_attributes = {
  .name = "imuBinarySem01"
};

void StartDefaultTask(void *argument);
extern void led_task(void *argument);
extern void imu_task(void *argument);
extern void usb_task(void *argument);
extern void referee_task(void *argument);
extern void chassis_task(void *argument);
extern void detect_task(void *argument);
extern void remote_control_task(void *argument);
extern void gimbal_task(void *argument);
extern void buzzer_task(void *argument);
extern void shoot_task(void *argument);
extern void watch_task(void *argument);
extern void ui_task(void *argument);
extern void auto_shoot_task(void *argument);

extern void MX_USB_DEVICE_Init(void);
void MX_FREERTOS_Init(void); /* (MISRA C 2004 rule 8.1) */

/* Hook prototypes */
void configureTimerForRunTimeStats(void);
unsigned long getRunTimeCounterValue(void);

/* USER CODE BEGIN 1 */
/* Functions needed when configGENERATE_RUN_TIME_STATS is on */
__weak void configureTimerForRunTimeStats(void)
{
	tick_init();
}

__weak unsigned long getRunTimeCounterValue(void)
{
	return tick_10us;
}
/* USER CODE END 1 */

void MX_FREERTOS_Init(void) {

  /* Create the semaphores(s) */
  /* creation of imuBinarySem01 */
  imuBinarySem01Handle = osSemaphoreNew(1, 1, &imuBinarySem01_attributes);

  /* Create the thread(s) */
  /* creation of defaultTask */
  defaultTaskHandle = osThreadNew(StartDefaultTask, NULL, &defaultTask_attributes);

  /* creation of ledTask */
  ledTaskHandle = osThreadNew(led_task, NULL, &ledTask_attributes);

  /* creation of imuTask */
  imuTaskHandle = osThreadNew(imu_task, NULL, &imuTask_attributes);

  /* creation of usbTask */
  usbTaskHandle = osThreadNew(usb_task, NULL, &usbTask_attributes);

  /* creation of refereeTask */
  refereeTaskHandle = osThreadNew(referee_task, NULL, &refereeTask_attributes);

  /* creation of chassisTask */
  chassisTaskHandle = osThreadNew(chassis_task, NULL, &chassisTask_attributes);

  /* creation of detectTask */
  detectTaskHandle = osThreadNew(detect_task, NULL, &detectTask_attributes);

  /* creation of remoteControlTa */
  remoteControlTaHandle = osThreadNew(remote_control_task, NULL, &remoteControlTa_attributes);

  /* creation of gimbalTask */
  gimbalTaskHandle = osThreadNew(gimbal_task, NULL, &gimbalTask_attributes);

  /* creation of buzzerTask */
  buzzerTaskHandle = osThreadNew(buzzer_task, NULL, &buzzerTask_attributes);

  /* creation of shootTask */
  shootTaskHandle = osThreadNew(shoot_task, NULL, &shootTask_attributes);

  /* creation of watchTask */
  watchTaskHandle = osThreadNew(watch_task, NULL, &watchTask_attributes);

  /* creation of uiTask */
  // uiTaskHandle = osThreadNew(ui_task, NULL, &uiTask_attributes);

  /* creation of autoShoot */
  // autoShootHandle = osThreadNew(auto_shoot_task, NULL, &autoShoot_attributes);

}

void StartDefaultTask(void *argument)
{
  /* init code for USB_DEVICE */
  MX_USB_DEVICE_Init();
  /* USER CODE BEGIN StartDefaultTask */
	/* Infinite loop */
	for (;;)
	{
		osThreadSuspend(osThreadGetId());
	}
  /* USER CODE END StartDefaultTask */
}
